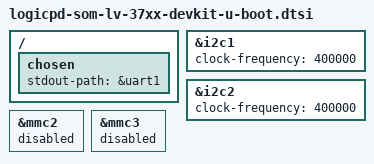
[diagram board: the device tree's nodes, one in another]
// SPDX-License-Identifier: GPL-2.0+
/*
 * Copyright (C) 2017
 * Logic PD - http://www.logicpd.com
 */

#include "omap3-u-boot.dtsi"

/ {
	chosen {
		stdout-path = &uart1;
	};
};

&i2c1 {
	clock-frequency = <400000>;
};

&i2c2 {
	clock-frequency = <400000>;
};

&mmc2 {
      status = "disabled";
};

&mmc3 {
      status = "disabled";
};

